# ATmega4808 register map
Vendor: Atmel; File version: 1.0
CPU: other r0p0, little endian, no MPU, no FPU, 4 interrupt priority bits
Registers are 8-bit, read-write, reset 0x0 unless marked. A register's access mark holds for its fields unless they carry their own. Offsets are from the block's base; [hi:lo] are bit positions; {n}, {i} and the like mark numbered series; 'fields as' and 'values as' point back to an identical list.

## SPI0 — Serial Peripheral Interface
Base 0x000008C0
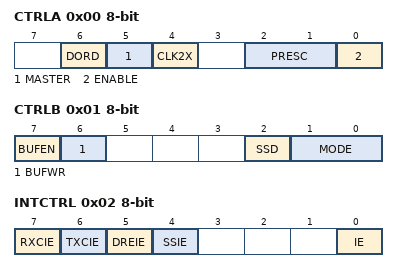
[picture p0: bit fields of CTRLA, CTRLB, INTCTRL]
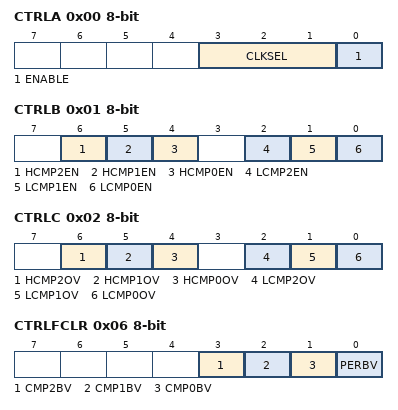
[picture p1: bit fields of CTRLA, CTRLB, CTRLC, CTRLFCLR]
0x00 CTRLA — Control A
  [6] DORD — Data Order Setting
  [5] MASTER — Host Operation Enable
  [4] CLK2X — Enable Double Speed
  [2:1] PRESC — Prescaler
    0=DIV4 (System Clock / 4); 1=DIV16 (System Clock / 16); 2=DIV64 (System Clock / 64); 3=DIV128 (System Clock / 128)
  [0] ENABLE — Enable Module
0x01 CTRLB — Control B
  [7] BUFEN — Buffer Mode Enable
  [6] BUFWR — Buffer Write Mode
  [2] SSD — Client Select Disable
  [1:0] MODE — SPI Mode
    {v}=SPI Mode {v} (v=0..3)
0x02 INTCTRL — Interrupt Control
  [7] RXCIE — Receive Complete Interrupt Enable
  [6] TXCIE — Transfer Complete Interrupt Enable
  [5] DREIE — Data Register Empty Interrupt Enable
  [4] SSIE — Client Select Trigger Interrupt Enable
  [0] IE — Interrupt Enable
0x03 INTFLAGS — Interrupt Flags
  [7] IF — Interrupt Flag
  [7] RXCIF — Receive Complete Interrupt Flag
  [6] TXCIF — Transfer Complete Interrupt Flag
  [6] WRCOL — Write Collision
  [5] DREIF — Data Register Empty Interrupt Flag
  [4] SSIF — Client Select Trigger Interrupt Flag
  [0] BUFOVF — Buffer Overflow
0x04 DATA

## SYSCFG — System Configuration Registers
Base 0x00000F01
0x00 REVID — Revision ID
0x01 EXTBRK — External Break
  [0] ENEXTBRK — External break enable
0x17 OCDM — OCD Message Register
0x18 OCDMS — OCD Message Status
  [0] OCDMR — OCD Message Read

## TCA0 — 16-bit Timer/Counter Type A
Base 0x00000A00
0x00 CTRLA — Control A
  [3:1] CLKSEL — Clock Selection
    0=DIV1 (System Clock); 1=DIV2 (System Clock / 2); 2=DIV4 (System Clock / 4); 3=DIV8 (System Clock / 8); 4=DIV16 (System Clock / 16); 5=DIV64 (System Clock / 64); 6=DIV256 (System Clock / 256); 7=DIV1024 (System Clock / 1024)
  [0] ENABLE — Module Enable
0x01 CTRLB — Control B
  [6] HCMP2EN — High Compare 2 Enable
  [5] HCMP1EN — High Compare 1 Enable
  [4] HCMP0EN — High Compare 0 Enable
  [2] LCMP2EN — Low Compare 2 Enable
  [1] LCMP1EN — Low Compare 1 Enable
  [0] LCMP0EN — Low Compare 0 Enable
0x02 CTRLC — Control C
  [6] HCMP2OV — High Compare 2 Output Value
  [5] HCMP1OV — High Compare 1 Output Value
  [4] HCMP0OV — High Compare 0 Output Value
  [2] LCMP2OV — Low Compare 2 Output Value
  [1] LCMP1OV — Low Compare 1 Output Value
  [0] LCMP0OV — Low Compare 0 Output Value
0x03 CTRLD — Control D
  [0] SPLITM — Split Mode Enable
0x04 CTRLECLR — Control E Clear
  [3:2] CMD — Command
    0=NONE (No Command); 1=UPDATE (Force Update); 2=RESTART (Force Restart); 3=RESET (Force Hard Reset)
0x05 CTRLESET — Control E Set
  fields as CTRLECLR
0x06 CTRLFCLR — Control F Clear
  [3] CMP2BV — Compare 2 Buffer Valid
  [2] CMP1BV — Compare 1 Buffer Valid
  [1] CMP0BV — Compare 0 Buffer Valid
  [0] PERBV — Period Buffer Valid
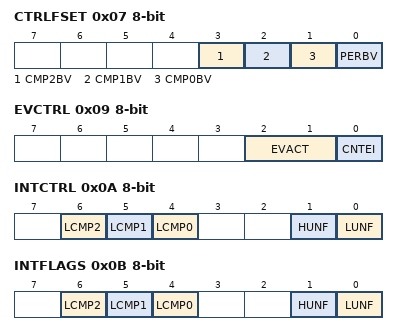
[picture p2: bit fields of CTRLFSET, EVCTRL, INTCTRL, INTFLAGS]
0x07 CTRLFSET — Control F Set
  fields as CTRLFCLR
0x09 EVCTRL — Event Control
  [2:1] EVACT — Event Action
    0=POSEDGE (Count on positive edge event); 1=ANYEDGE (Count on any edge event); 2=HIGHLVL (Count on prescaled clock while event line is 1.); 3=UPDOWN (Count on prescaled clock. Event controls count direction. Up-count when event line is 0, down-count when event line is 1.)
  [0] CNTEI — Count on Event Input
0x0A INTCTRL — Interrupt Control
  [6] LCMP2 — Low Compare 2 Interrupt Enable
  [5] LCMP1 — Low Compare 1 Interrupt Enable
  [4] LCMP0 — Low Compare 0 Interrupt Enable
  [1] HUNF — High Underflow Interrupt Enable
  [0] LUNF — Low Underflow Interrupt Enable
0x0B INTFLAGS — Interrupt Flags
  [6] LCMP2 — Low Compare 0 Interrupt Flag
  [5] LCMP1 — Low Compare 1 Interrupt Flag
  [4] LCMP0 — Low Compare 2 Interrupt Flag
  [1] HUNF — High Underflow Interrupt Flag
  [0] LUNF — Low Underflow Interrupt Flag
0x0E DBGCTRL — Degbug Control
  [0] DBGRUN — Debug Run
0x0F TEMP — Temporary data for 16-bit Access
0x20 CNT 16-bit (reset mask 0xFF) — Count
0x20 LCNT — Low Count
0x21 HCNT — High Count
0x26 LPER — Low Period
0x26 PER 16-bit (reset mask 0xFF) — Period
0x27 HPER — High Period
{0x28+2i} CMP{i} 16-bit (reset mask 0xFF) (i=0..2) — Compare {i}
{0x28+2i} LCMP{i} (i=0..2) — Low Compare
{0x29+2i} HCMP{i} (i=0..2) — High Compare
0x36 PERBUF 16-bit (reset mask 0xFF) — Period Buffer
{0x38+2i} CMP{i}BUF 16-bit (reset mask 0xFF) (i=0..2) — Compare {i} Buffer
